# R9A02G021 register map
Vendor: Renesas Electronics Corporation; Series: RISC-V; File version: 1.10.00 + 202304131714_CPU
CPU: other r0p0, little endian, no MPU, no FPU, VTOR, 4 interrupt priority bits, 32 interrupts
Registers are 8-bit, read-write, reset 0x0 unless marked. A register's access mark holds for its fields unless they carry their own. Offsets are from the block's base; [hi:lo] are bit positions; {n}, {i} and the like mark numbered series; 'fields as' and 'values as' point back to an identical list.

## TAU — Timer Array Unit
Base 0x40095000
{0x0+2i} TDR{i:02} 16-bit (i=0..7) — Timer Data Register {i:02}
0x02 TDR01L (alternate view of TDR01) — Timer Data Register 01
0x03 TDR01H (alternate view of TDR01) — Timer Data Register 01
0x06 TDR03L (alternate view of TDR03) — Timer Data Register 03
0x07 TDR03H (alternate view of TDR03) — Timer Data Register 03
{0x80+2i} TCR0{i} (i=0..7) 16-bit ro reset 0xFFFF — Timer Counter Register 0{i}
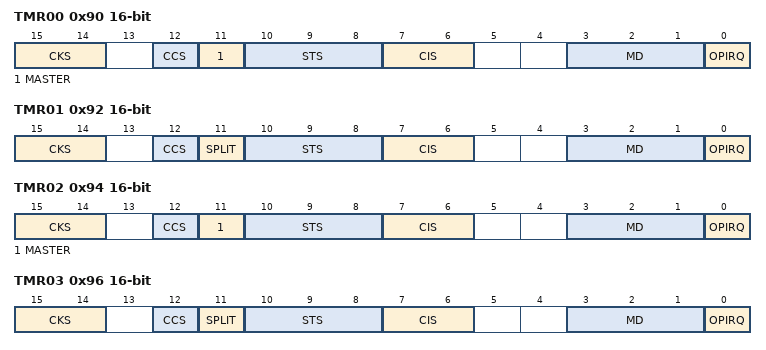
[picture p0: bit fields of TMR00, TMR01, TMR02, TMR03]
0x90 TMR00 16-bit — Timer Mode Register 00
  [15:14] CKS — Selection of operation clock (fMCK) of channel n
    0=Operation clock CK00 set by timer clock select register 0 (TPS0); 1=Operation clock CK02 set by timer clock select register 0 (TPS0); 2=Operation clock CK01 set by timer clock select register 0 (TPS0); 3=Operation clock CK03 set by timer clock select register 0 (TPS0)
  [12] CCS — Selection of counter clock (fTCLK) of channel n
    0=Operating clock (fMCK) specified by the CKS[1:0] bits; 1=Valid edge of input signal input from the TI0n pin. In channel 5, valid edge of input signal selected by the TIS0 registerIn channel 7, valid edge of input signal selected by the ISC register
  [11] MASTER — Selection between using channel n independently or simultaneously with another channel (as a slave or master)
    0=Operates in independent channel operation function or as slave channel in simultaneous channel operation function; 1=Operates as master channel in simultaneous channel operation function
  [10:8] STS — Setting of start trigger or capture trigger of channel n
    0=Only software trigger start is valid (other trigger sources are unselected); 1=Valid edge of the TI0n pin input is used as both the start trigger and capture trigger; 2=Both the edges of the TI0n pin input are used as a start trigger and a capture trigger; 4=Interrupt signal of the master channel is used (when the channel is used as a slave channel with the simultaneous channel operation function); other=Others (Setting prohibited)
  [7:6] CIS — Selection of TI0n pin input valid edge
    0=Falling edge; 1=Rising edge; 2=Both edges (when low-level width is measured) Start trigger: Falling edge, Capture trigger: Rising edge; 3=Both edges (when high-level width is measured) Start trigger: Rising edge, Capture trigger: Falling edge
  [3:1] MD — Selection of operation mode at channel n
    0=Interval timer mode; 2=Capture mode; 3=Event counter mode; 4=One-count mode; 6=Capture and one-count mode; other=Others (Setting prohibited)
  [0] OPIRQ — Setting of starting count and interrupt
0x92 TMR01 16-bit — Timer Mode Register 01
  [15:14] CKS — Selection of operation clock (fMCK) of channel n
    values as TMR00.CKS
  [12] CCS — Selection of counter clock (fTCLK) of channel n
    0=Operating clock (fMCK) specified by the CKS[1:0] bits; 1=Valid edge of input signal input from the TI0n pin
  [11] SPLIT — Selection of 8 or 16-bit timer operation for channels 1 and 3
    0=Operates as 16-bit timer (Operates in independent channel operation function or as slave channel in simultaneous channel operation function.); 1=Operates as 8-bit timer
  [10:8] STS — Setting of start trigger or capture trigger of channel n
    values as TMR00.STS
  [7:6] CIS — Selection of TI0n pin input valid edge
    values as TMR00.CIS
  [3:1] MD — Selection of operation mode at channel n
    0=Interval timer mode; 2=Capture mode; 3=Event counter mode; 4=One-count mode; 6=Capture & one-count mode; other=Others (Setting prohibited)
  [0] OPIRQ — Setting of starting count and interrupt
0x94 TMR02 16-bit — Timer Mode Register 02
  fields as TMR00
0x96 TMR03 16-bit — Timer Mode Register 03
  fields as TMR01
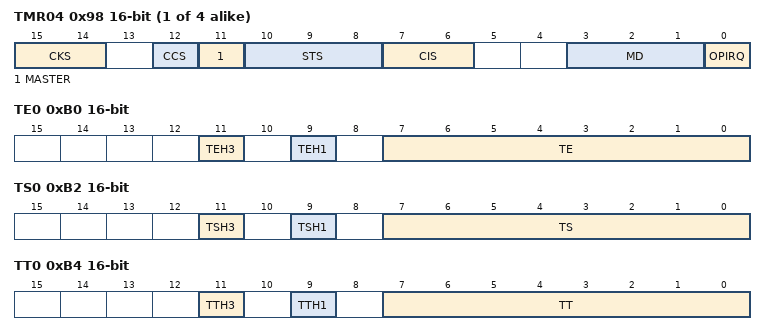
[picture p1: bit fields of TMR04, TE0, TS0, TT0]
{0x90+2i} TMR{i:02} 16-bit (i=4..7) — Timer Mode Register {i:02}
  fields as TMR00
{0xA0+2i} TSR0{i} (i=0..7) 16-bit ro — Timer Status Register 0{i}
  [0] OVF — Counter overflow state of channel n
    0=Overflow does not occur; 1=Overflow occurs
0xB0 TE0 16-bit ro — Timer Channel Enable Status Register 0
  [all] fields
    0=Operation is disabled; 1=Operation is enabled
  [11] TEH3 — Indication of whether operation of the higher 8-bit timer is enabled or disabled when channel 3 is in the 8-bit timer mode
  [9] TEH1 — Indication of whether operation of the higher 8-bit timer is enabled or disabled when channel 1 is in the 8-bit timer mode
  [7:0] TE — Indication of operation enabled or disabled state of channel n
0xB2 TS0 16-bit — Timer Channel Start Register 0
  [11] TSH3 — Trigger to enable operation (start operation) of the higher 8-bit timer when channel 3 is in the 8-bit timer mode
    0=No trigger operation; 1=The TE0.TEH3 bit is set to 1 and the count operation becomes enabled
  [9] TSH1 — Trigger to enable operation (start operation) of the higher 8-bit timer when channel 1 is in the 8-bit timer mode
    0=No trigger operation; 1=The TE0.TEH1 bit is set to 1 and the count operation becomes enabled
  [7:0] TS — Operation enable (start) trigger of channel n
    0=No trigger operation; 1=The TE0.TE[n] bit is set to 1 and the count operation becomes enabled
0xB4 TT0 16-bit — Timer Channel Stop Register 0
  [11] TTH3 — Trigger to stop operation of the higher 8-bit timer when channel 3 is in the 8-bit timer mode
    0=No trigger operation; 1=The TE0.TEH3 bit is cleared to 0 and the count operation is stopped
  [9] TTH1 — Trigger to stop operation of the higher 8-bit timer when channel 1 is in the 8-bit timer mode
    0=No trigger operation; 1=The TE0.TEH1 bit is cleared to 0 and the count operation is stopped
  [7:0] TT — Operation stop trigger of channel n
    0=No trigger operation; 1=The TE0.TE[n] bit is cleared to 0 and the count operation is stopped
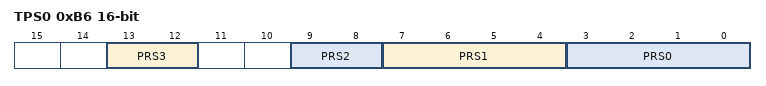
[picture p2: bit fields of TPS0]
0xB6 TPS0 16-bit — Timer Clock Select Register 0
  [13:12] PRS3 — Selection of operation clock (CK03)
    0=PCLKB/28; 1=PCLKB/210; 2=PCLKB/212; 3=PCLKB/214
  [9:8] PRS2 — Selection of operation clock (CK02)
    0=PCLKB/2; 1=PCLKB/22; 2=PCLKB/24; 3=PCLKB/26
  [7:4] PRS1 — Selection of operation clock (CK01)
    0=PCLKB; 1=PCLKB/2; {v}=PCLKB/{v+20} (v=2..9); {v}=PCLKB/{v+200} (v=10..15)
  [3:0] PRS0 — Selection of operation clock (CK00)
    values as PRS1
0xB8 TO0 16-bit — Timer Output Register 0
  [7:0] TO — Timer output of channel n
    0=Timer output value is 0; 1=Timer output value is 1
0xBA TOE0 16-bit — Timer Output Enable Register 0
  [7:0] TOE — Enabling or disabling timer output for channel n
    0=Disables timer output; 1=Enables timer output
0xBC TOL0 16-bit — Timer Output Level Register 0
  [7:1] TOL — Control of timer output of channel n
    0=Positive logic output (active-high); 1=Negative logic output (active-low)
0xBE TOM0 16-bit — Timer Output Mode Register 0
  [7:1] TOM — Control of timer output mode of channel n
    0=Master channel output mode (to produce toggled output by timer interrupt request signal (TAU0_ENDIn)); 1=Slave channel output mode (output is set by the timer interrupt request signal (TAU0_ENDIn) of the master channel, and reset by the timer interrupt request signal (TAU0_ENDIp) of the slave channel)
